# PIC32MM0016GPL020 device description
Architecture: MIPS; Family: PIC32MM1324; Series: PIC32MM
Registers are 32-bit, read-write, no defined reset value unless marked. A register's access mark holds for its fields unless they carry their own. Offsets are from the block's base; [hi:lo] are bit positions; {n}, {i} and the like mark numbered series.

## ADC
Instances: ADC 0x1f800700 in periph0
{0x0+0x10*i} ADC1BUF{i} (i=0..15)
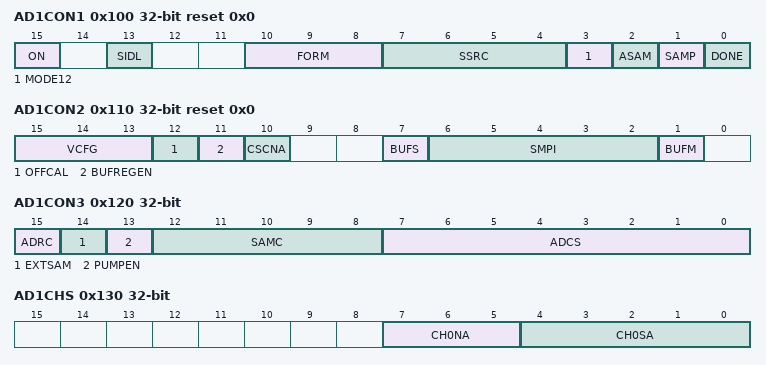
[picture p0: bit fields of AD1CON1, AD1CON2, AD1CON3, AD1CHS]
0x100 AD1CON1 reset 0x0 — ADC Control Register 1
  [15] ON — ADC Operating Mode bit
    1=ADC module is operating; 0=ADC module is not operating
  [13] SIDL — Stop in Idle Mode bit
    1=Discontinue module operation when device enters Idle mode; 0=Continue module operation in Idle mode
  [10:8] FORM — Data Output Format bits
    3=Signed Fractional 16-bit; 2=Fractional 16-bit; 1=Signed Integer 16-bit; 0=Integer 16-bit; 7=Signed Fractional 32-bit; 6=Fractional 32-bit; 5=Signed Integer 32-bit; 4=Integer 32-bit
  [7:4] SSRC — Conversion Trigger Source Select bits
    12=CLC2 module event ends sampling and starts conversion; 11=CLC1 module event ends sampling and starts conversion; 10=SCCP3 module event ends sampling and starts conversion; 9=SCCP2 module event ends sampling and starts conversion; 8=MCCP1 module event ends sampling and starts conversion; 7=Internal counter ends sampling and starts conversion (auto convert); 6=Timer1 period match ends sampling and starts conversion (can trigger during Sleep mode); 5=Timer1 period match ends sampling and starts conversion (will not trigger during Sleep mode); 1=Active transition on INT0 pin ends sampling and starts conversion; 0=Clearing SAMP bit ends sampling and starts conversion
  [3] MODE12 — ADC Operation Mode
    1=12-bit ADC operation; 0=10-bit ADC operation
  [2] ASAM — ADC Sample Auto-Start bit
    1=Sampling begins immediately after last conversion completes; SAMP bit is automatically set; 0=Sampling begins when SAMP bit is set
  [1] SAMP — ADC Sample Enable bit
    1=The ADC sample and hold amplifier is sampling; 0=The ADC sample/hold amplifier is holding
  [0] DONE — Analog-to-Digital Conversion Status bit
    1=Analog-to-digital conversion is done; 0=Analog-to-digital conversion is not done or has not started
0x110 AD1CON2 reset 0x0
  [15:13] VCFG — Voltage Reference Configuration bits
    0=VREFH is AVDD and VREFL is AVSS; 2=VREFH is External VREF + pin and VREFL is AVSS; 1=VREFH is AVDD and VREFL is External VREF- pin; 3=VREFH is External VREF+ pin and VREFL is External VREF- pin
  [12] OFFCAL — Input Offset Calibration Mode Select bit
    1=Enable Offset Calibration mode; Positive and negative inputs of the sample and hold amplifier are connected to negative reference; 0=Disable Offset Calibration mode; The inputs to the sample and hold amplifier are controlled by AD1CHS or AD1CSS
  [11] BUFREGEN
  [10] CSCNA — Input Scan Select bit
    1=Scan inputs; 0=Do not scan inputs
  [7] BUFS — Buffer Fill Status bit
    1=ADC is currently filling buffer 8-15; user should access data in 0-7; 0=ADC is currently filling buffer 0-7; user should access data in 8-15
  [6:2] SMPI — Sample/Convert Sequences Per Interrupt Selection bits
    {v}=Interrupts at the completion of conversion for each {v+1}th sample/convert sequence (v=3..15); 2=Interrupts at the completion of conversion for each 3rd sample/convert sequence; 1=Interrupts at the completion of conversion for each 2nd sample/convert sequence; 0=Interrupts at the completion of conversion for each sample/convert sequence
  [1] BUFM — ADC Result Buffer Mode Select bit
    1=Buffer configured as two 8-word buffers ADC1BUF7-ADC1BUF0 / ADC1BUF15-ADCBUF8; 0=Buffer configured as one 16-word buffer ADC1BUF15-ADC1BUF0
0x120 AD1CON3
  [15] ADRC — ADC Conversion Clock Source bit
    1=Clock derived from FRC; 0=Clock derived from Peripheral Bus Clock (PBCLK)
  [14] EXTSAM — Extended Sampling Time bit
    1=ADC is still sampling after SAMP bit = 0; 0=ADC stops sampling when SAMP bit = 0
  [13] PUMPEN
  [12:8] SAMC — Auto-Sample Time bits
    {v}={v} TAD (v=1..31)
  [7:0] ADCS — ADC Conversion Clock Select bits
    255=510*TPB; 254=508*TPB; 253=506*TPB; 252=504*TPB; 251=502*TPB; 250=500*TPB; 249=498*TPB; 248=496*TPB; 247=494*TPB; 246=492*TPB; 245=490*TPB; 244=488*TPB; 243=486*TPB; 242=484*TPB; 241=482*TPB; 240=480*TPB; 239=478*TPB; 238=476*TPB; 237=474*TPB; 236=472*TPB; 235=470*TPB; 234=468*TPB; 233=466*TPB; 232=464*TPB; 231=462*TPB; 230=460*TPB; 229=458*TPB; 228=456*TPB; 227=454*TPB; 226=452*TPB; 225=450*TPB; 224=448*TPB; 223=446*TPB; 222=444*TPB; 221=442*TPB; 220=440*TPB; 219=438*TPB; 218=436*TPB; 217=434*TPB; 216=432*TPB; 215=430*TPB; 214=428*TPB; 213=426*TPB; 212=424*TPB; 211=422*TPB; 210=420*TPB; 209=418*TPB; 208=416*TPB; 207=414*TPB; 206=412*TPB; 205=410*TPB; 204=408*TPB; 203=406*TPB; 202=404*TPB; 201=402*TPB; 200=400*TPB; 199=398*TPB; 198=396*TPB; 197=394*TPB; 196=392*TPB; 195=390*TPB; 194=388*TPB; 193=386*TPB; 192=384*TPB; 191=382*TPB; 190=380*TPB; 189=378*TPB; 188=376*TPB; 187=374*TPB; 186=372*TPB; 185=370*TPB; 184=368*TPB; 183=366*TPB; 182=364*TPB; 181=362*TPB; 180=360*TPB; 179=358*TPB; 178=356*TPB; 177=354*TPB; 176=352*TPB; 175=350*TPB; 174=348*TPB; 173=346*TPB; 172=344*TPB; 171=342*TPB; 170=340*TPB; 169=338*TPB; 168=336*TPB; 167=334*TPB; 166=332*TPB; 165=330*TPB; 164=328*TPB; 163=326*TPB; 162=324*TPB; 161=322*TPB; 160=320*TPB; 159=318*TPB; 158=316*TPB; 157=314*TPB; 156=312*TPB; 155=310*TPB; 154=308*TPB; 153=306*TPB; 152=304*TPB; 151=302*TPB; 150=300*TPB; 149=298*TPB; 148=296*TPB; 147=294*TPB; 146=292*TPB; 145=290*TPB; 144=288*TPB; 143=286*TPB; 142=284*TPB; 141=282*TPB; 140=280*TPB; 139=278*TPB; 138=276*TPB; 137=274*TPB; 136=272*TPB; 135=270*TPB; 134=268*TPB; 133=266*TPB; 132=264*TPB; 131=262*TPB; 130=260*TPB; 129=258*TPB; 128=256*TPB; 127=254*TPB; 126=252*TPB; 125=250*TPB; 124=248*TPB; 123=246*TPB; 122=244*TPB; 121=242*TPB; 120=240*TPB; 119=238*TPB; 118=236*TPB; 117=234*TPB; 116=232*TPB; 115=230*TPB; 114=228*TPB; 113=226*TPB; 112=224*TPB; 111=222*TPB; 110=220*TPB; 109=218*TPB; 108=216*TPB; 107=214*TPB; 106=212*TPB; 105=210*TPB; 104=208*TPB; 103=206*TPB; 102=204*TPB; 101=202*TPB; 100=200*TPB; 99=198*TPB; 98=196*TPB; 97=194*TPB; 96=192*TPB; 95=190*TPB; 94=188*TPB; 93=186*TPB; 92=184*TPB; 91=182*TPB; 90=180*TPB; 89=178*TPB; 88=176*TPB; 87=174*TPB; 86=172*TPB; 85=170*TPB; 84=168*TPB; 83=166*TPB; 82=164*TPB; 81=162*TPB; 80=160*TPB; 79=158*TPB; 78=156*TPB; 77=154*TPB; 76=152*TPB; 75=150*TPB; 74=148*TPB; 73=146*TPB; 72=144*TPB; 71=142*TPB; 70=140*TPB; 69=138*TPB; 68=136*TPB; 67=134*TPB; 66=132*TPB; 65=130*TPB; 64=128*TPB; 63=126*TPB; 62=124*TPB; 61=122*TPB; 60=120*TPB; 59=118*TPB; 58=116*TPB; 57=114*TPB; 56=112*TPB; 55=110*TPB; 54=108*TPB; 53=106*TPB; 52=104*TPB; 51=102*TPB; 50=100*TPB; 49=98*TPB; 48=96*TPB; 47=94*TPB; 46=92*TPB; 45=90*TPB; 44=88*TPB; 43=86*TPB; 42=84*TPB; 41=82*TPB; 40=80*TPB; 39=78*TPB; 38=76*TPB; 37=74*TPB; 36=72*TPB; 35=70*TPB; 34=68*TPB; 33=66*TPB; 32=64*TPB; 31=62*TPB; 30=60*TPB; 29=58*TPB; 28=56*TPB; 27=54*TPB; 26=52*TPB; 25=50*TPB; 24=48*TPB; 23=46*TPB; 22=44*TPB; 21=42*TPB; 20=40*TPB; 19=38*TPB; 18=36*TPB; 17=34*TPB; 16=32*TPB; 15=30*TPB; 14=28*TPB; 13=26*TPB; 12=24*TPB; 11=22*TPB; 10=20*TPB; 9=18*TPB; 8=16*TPB; 7=14*TPB; 6=12*TPB; 5=10*TPB; 4=8*TPB; 3=6*TPB; 2=4*TPB; 1=2*TPB; 0=1*TPB
0x130 AD1CHS
  [7:5] CH0NA — Negative Input Select bit
    0=AVSS (Negative input is AVSS)
  [4:0] CH0SA — Positive Input Select bits
    30=AVDD (Positive input is AVDD); 29=AVSS (Positive input is AVSS); 28=VBG (Positive input is Band Gape Reference (VBG)); 27=VDDCORE (Positive input is VDD Core); {v}=AN{v} (Positive input is AN{v}) (v=0..19)
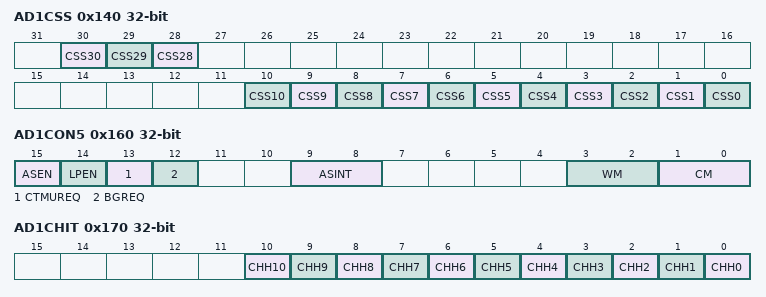
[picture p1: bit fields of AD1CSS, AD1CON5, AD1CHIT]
0x140 AD1CSS
  [30] CSS30 — AVDD Scan Selection bits
    1=Select AVDD for input scan; CSS30 = AVDD; 0=Skip AVDD for input scan; CSS30 = AVDD
  [29] CSS29 — AVSS Scan Selection bits
    1=Select AVSS for input scan; CSS29 = AVSS; 0=Skip AVSS for input scan; CSS29 = AVSS
  [28] CSS28 — VBG Scan Selection bits
    1=Select VBG for input scan; CSS28 = VBG; 0=Skip VBG for input scan; CSS28 = VBG
  [n] CSS{n} (n=0..10) — AN{n} Pin Scan Selection bits
    1=Select AN{n} for input scan; CSS{n} = AN{n}; 0=Skip AN{n} for input scan; CSS{n} = AN{n}
0x160 AD1CON5
  [15] ASEN
  [14] LPEN
  [13] CTMUREQ
  [12] BGREQ
  [9:8] ASINT
  [3:2] WM
  [1:0] CM — Compare mode bits
    3=Outside Window mode; 2=Inside Window mode; 1=Greater Than mode; 0=Less Than mode
0x170 AD1CHIT
  [n] CHH{n} (n=0..10)
Value list AD1CSS__CSS11: 0x00000800=Select AN11 for input scan; CSS11 = AN11; 0=Skip AN11 for input scan; CSS11 = AN11
Value list AD1CSS__CSS12: 0x00001000=Select AN12 for input scan; CSS12 = AN12; 0=Skip AN12 for input scan; CSS12 = AN12
Value list AD1CSS__CSS13: 0x00002000=Select AN13 for input scan; CSS13 = AN13; 0=Skip AN13 for input scan; CSS13 = AN13
Value list AD1CSS__CSS14: 0x00004000=Select AN14 for input scan; CSS14 = AN14; 0=Skip AN14 for input scan; CSS14 = AN14
Value list AD1CSS__CSS15: 0x00008000=Select AN15 for input scan; CSS15 = AN15; 0=Skip AN15 for input scan; CSS15 = AN15
Value list AD1CSS__CSS16: 0x10000=Select AN16 for input scan; CSS16 = AN16; 0=Skip AN16 for input scan; CSS16 = AN16
Value list AD1CSS__CSS17: 0x20000=Select AN17 for input scan; CSS17 = AN17; 0=Skip AN17 for input scan; CSS17 = AN17
Value list AD1CSS__CSS18: 0x40000=Select AN18 for input scan; CSS18 = AN18; 0=Skip AN18 for input scan; CSS18 = AN18
Value list AD1CSS__CSS19: 0x80000=Select AN19 for input scan; CSS19 = AN19; 0=Skip AN19 for input scan; CSS19 = AN19
Value list AD1CSS__CSS27: 0x8000000=Select VDDCORE for input scan; CSS27 = VDDCORE; 0=Skip VDDCORE for input scan; CSS27 = VDDCORE

## Notices in the file
Copyright (c) 2019 Microchip Technology Inc.
SPDX-License-Identifier: Apache-2.0
Licensed under the Apache License, Version 2.0 (the "License");
you may not use this file except in compliance with the License.
You may obtain a copy of the License at
http://www.apache.org/licenses/LICENSE-2.0
Unless required by applicable law or agreed to in writing, software
distributed under the License is distributed on an "AS IS" BASIS,
WITHOUT WARRANTIES OR CONDITIONS OF ANY KIND, either express or implied.
See the License for the specific language governing permissions and
limitations under the License.
